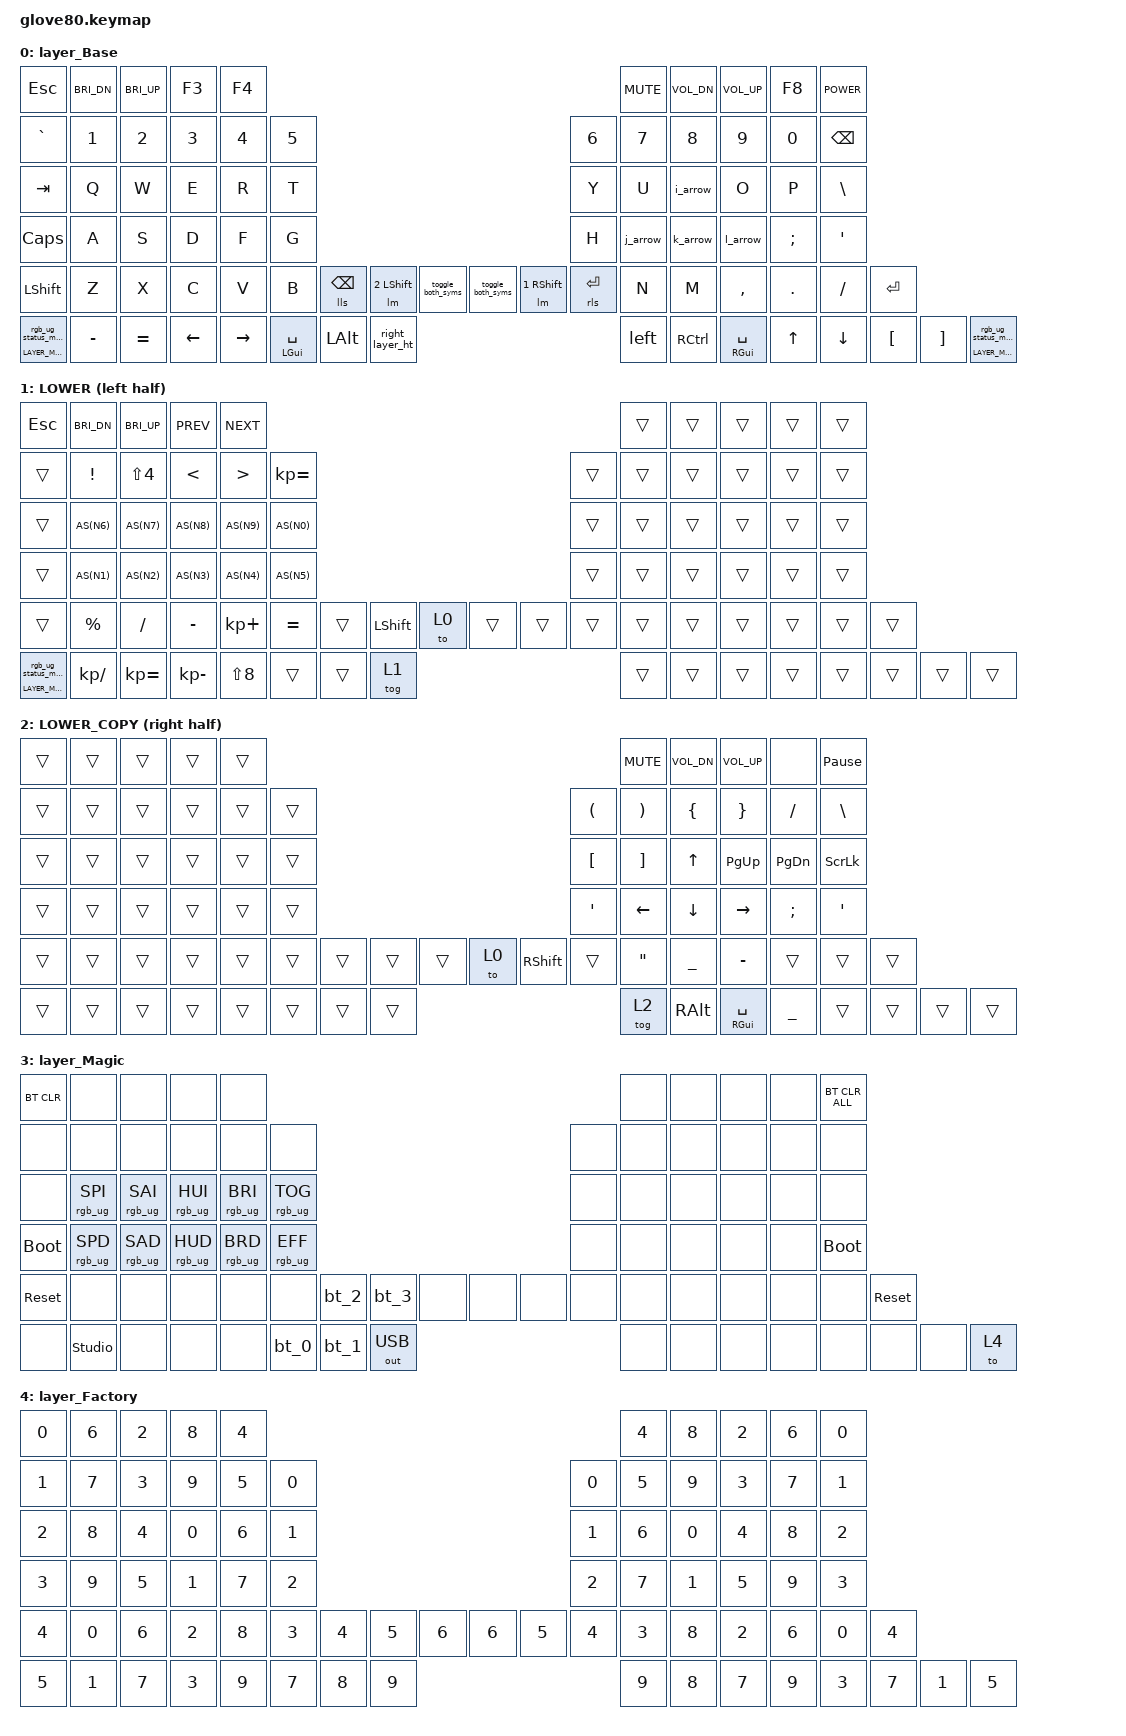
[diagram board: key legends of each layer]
/*
 * Copyright (c) 2020 The ZMK Contributors
 * Copyright (c) 2025 Innaworks Development Limited, trading as MoErgo
 *
 * SPDX-License-Identifier: MIT
 */
/* THIS FILE WAS GENERATED BY GLOVE80 LAYOUT EDITOR
 *
 * This file was generated automatically. You may or may not want to
 * edit it directly.
 */
/* Include all behavior includes needed */

#include <behaviors.dtsi>
#include <dt-bindings/zmk/bt.h>
#include <dt-bindings/zmk/keys.h>
#include <dt-bindings/zmk/outputs.h>
#include <dt-bindings/zmk/rgb.h>

/* On demand includes */
/* Automatically generated layer name #define */

#define LAYER_Base 0
#define LAYER_Left 1
#define LAYER_Right 2
#define LAYER_Magic 3
#define LAYER_Factory 4

/* To deal with the situation where there is no Lower layer, to keep &lower happy */
    /* Custom Device-tree */
#ifndef LAYER_Lower

#define LAYER_Lower 0

#endif
#define AS(keycode) &as LS(keycode) keycode
/{

    /* Input Listeners */
    /* System behavior and Macros */



    behaviors {
        // For the "layer" key, it'd nice to be able to use it as either a shift or a toggle.
        // Configure it as a tap dance, so the first tap (or hold) is a &mo and the second tap is a &to


        toggle_both_syms: toggle_both_syms {
            compatible = "zmk,behavior-macro";
            #binding-cells = <0>;
            wait-ms = <0>;
            tap-ms = <0>;
            bindings =
                <&macro_press>,
                <&tog LAYER_Left &tog LAYER_Right>,
                <&macro_release>;
        };

        left: left {
            compatible = "zmk,behavior-tap-dance";
            #binding-cells = <0>;
            tapping-term-ms = <200>;
            bindings = <&mo LAYER_Left>, <&to LAYER_Left>;
        };


        right_layer_ht: right_layer_ht {
            compatible = "zmk,behavior-tap-dance";           
            #binding-cells = <0>;
            tapping-term-ms = <200>;
            bindings = <&mo 2>, <&to 2>;  
        };

        mt_space_gui: mt_space_gui {
            compatible = "zmk,behavior-hold-tap";
            #binding-cells = <2>;
            flavor = "tap-preferred";      /* quicker to recognise holds */
            tapping-term-ms = <150>;  
            bindings = <&kp  &kp>;
        };
    };
};

/ {
    macros {
        rgb_ug_status_macro: rgb_ug_status_macro {
            compatible = "zmk,behavior-macro";
            #binding-cells = <0>;
            bindings = <&rgb_ug RGB_STATUS>;
        };
        lm: lm {
            compatible = "zmk,behavior-macro-two-param";
            wait-ms = <0>;
            tap-ms = <0>;
            #binding-cells = <2>;
            bindings
                = <&macro_param_1to1>
                , <&macro_press &mo MACRO_PLACEHOLDER>
                , <&macro_param_2to1>
                , <&macro_press &kp MACRO_PLACEHOLDER>
                , <&macro_pause_for_release>
                , <&macro_param_2to1>
                , <&macro_release &kp MACRO_PLACEHOLDER>
                , <&macro_param_1to1>
                , <&macro_release &mo MACRO_PLACEHOLDER>
                ;
        };

        lls: lls {
            compatible = "zmk,behavior-macro";
            #binding-cells = <0>;
            bindings
                = <&macro_press &lm 2 LSHIFT>
                , <&macro_pause_for_release>
                , <&macro_release &lm 2 LSHIFT>
                 ;
        };

        rls: rls {
            compatible = "zmk,behavior-macro";
            #binding-cells = <0>;
            bindings
                = <&macro_press &lm 1 RSHIFT>
                , <&macro_pause_for_release>
                , <&macro_release &lm 1 RSHIFT>
                 ;
        };
        
        
        
    };
};

/ {
    #ifdef BT_DISC_CMD

    behaviors {
        bt_0: bt_0 {
            compatible = "zmk,behavior-tap-dance";
            #binding-cells = <0>;
            tapping-term-ms = <200>;
            bindings = <&bt_select_0>, <&bt BT_DISC 0>;
        };

        bt_1: bt_1 {
            compatible = "zmk,behavior-tap-dance";
            #binding-cells = <0>;
            tapping-term-ms = <200>;
            bindings = <&bt_select_1>, <&bt BT_DISC 1>;
        };

        bt_2: bt_2 {
            compatible = "zmk,behavior-tap-dance";
            #binding-cells = <0>;
            tapping-term-ms = <200>;
            bindings = <&bt_select_2>, <&bt BT_DISC 2>;
        };

        bt_3: bt_3 {
            compatible = "zmk,behavior-tap-dance";
            #binding-cells = <0>;
            tapping-term-ms = <200>;
            bindings = <&bt_select_3>, <&bt BT_DISC 3>;
        };
    };

    macros {
        bt_select_0: bt_select_0 {
            compatible = "zmk,behavior-macro";
            #binding-cells = <0>;
            bindings = <&out OUT_BLE &bt BT_SEL 0>;
        };

        bt_select_1: bt_select_1 {
            compatible = "zmk,behavior-macro";
            #binding-cells = <0>;
            bindings = <&out OUT_BLE &bt BT_SEL 1>;
        };

        bt_select_2: bt_select_2 {
            compatible = "zmk,behavior-macro";
            #binding-cells = <0>;
            bindings = <&out OUT_BLE &bt BT_SEL 2>;
        };

        bt_select_3: bt_select_3 {
            compatible = "zmk,behavior-macro";
            #binding-cells = <0>;
            bindings = <&out OUT_BLE &bt BT_SEL 3>;
        };
    };

    #else

    macros {
        bt_0: bt_0 {
            compatible = "zmk,behavior-macro";
            #binding-cells = <0>;
            bindings = <&out OUT_BLE &bt BT_SEL 0>;
        };

        bt_1: bt_1 {
            compatible = "zmk,behavior-macro";
            #binding-cells = <0>;
            bindings = <&out OUT_BLE &bt BT_SEL 1>;
        };

        bt_2: bt_2 {
            compatible = "zmk,behavior-macro";
            #binding-cells = <0>;
            bindings = <&out OUT_BLE &bt BT_SEL 2>;
        };

        bt_3: bt_3 {
            compatible = "zmk,behavior-macro";
            #binding-cells = <0>;
            bindings = <&out OUT_BLE &bt BT_SEL 3>;
        };
    };

    #endif
};

/ {
    behaviors {
        magic: magic {
            compatible = "zmk,behavior-hold-tap";
            #binding-cells = <2>;
            flavor = "tap-preferred";
            tapping-term-ms = <200>;
            bindings = <&mo>, <&rgb_ug_status_macro>;
        };
        lmht: lmht {
            compatible = "zmk,behavior-hold-tap";
            flavor = "tap-preferred";
            tapping-term-ms = <300>;
            #binding-cells = <2>;
            bindings = <&lls>, <&kp >;
        };
        rmht: rmht {
            compatible = "zmk,behavior-hold-tap";
            flavor = "tap-preferred";
            tapping-term-ms = <300>;
            #binding-cells = <2>;
            bindings = <&rls>, <&kp>;
        }; 
    };
};

/* #define for key positions */

#define POS_LH_T1 52
#define POS_LH_T2 53
#define POS_LH_T3 54
#define POS_LH_T4 69
#define POS_LH_T5 70
#define POS_LH_T6 71
#define POS_LH_C1R2 15
#define POS_LH_C1R3 27
#define POS_LH_C1R4 39
#define POS_LH_C1R5 51
#define POS_LH_C2R1 4
#define POS_LH_C2R2 14
#define POS_LH_C2R3 26
#define POS_LH_C2R4 38
#define POS_LH_C2R5 50
#define POS_LH_C2R6 68
#define POS_LH_C3R1 3
#define POS_LH_C3R2 13
#define POS_LH_C3R3 25
#define POS_LH_C3R4 37
#define POS_LH_C3R5 49
#define POS_LH_C3R6 67
#define POS_LH_C4R1 2
#define POS_LH_C4R2 12
#define POS_LH_C4R3 24
#define POS_LH_C4R4 36
#define POS_LH_C4R5 48
#define POS_LH_C4R6 66
#define POS_LH_C5R1 1
#define POS_LH_C5R2 11
#define POS_LH_C5R3 23
#define POS_LH_C5R4 35
#define POS_LH_C5R5 47
#define POS_LH_C5R6 65
#define POS_LH_C6R1 0
#define POS_LH_C6R2 10
#define POS_LH_C6R3 22
#define POS_LH_C6R4 34
#define POS_LH_C6R5 46
#define POS_LH_C6R6 64
#define POS_RH_T1 57
#define POS_RH_T2 56
#define POS_RH_T3 55
#define POS_RH_T4 74
#define POS_RH_T5 73
#define POS_RH_T6 72
#define POS_RH_C1R2 16
#define POS_RH_C1R3 28
#define POS_RH_C1R4 40
#define POS_RH_C1R5 58
#define POS_RH_C2R1 5
#define POS_RH_C2R2 17
#define POS_RH_C2R3 29
#define POS_RH_C2R4 41
#define POS_RH_C2R5 59
#define POS_RH_C2R6 75
#define POS_RH_C3R1 6
#define POS_RH_C3R2 18
#define POS_RH_C3R3 30
#define POS_RH_C3R4 42
#define POS_RH_C3R5 60
#define POS_RH_C3R6 76
#define POS_RH_C4R1 7
#define POS_RH_C4R2 19
#define POS_RH_C4R3 31
#define POS_RH_C4R4 43
#define POS_RH_C4R5 61
#define POS_RH_C4R6 77
#define POS_RH_C5R1 8
#define POS_RH_C5R2 20
#define POS_RH_C5R3 32
#define POS_RH_C5R4 44
#define POS_RH_C5R5 62
#define POS_RH_C5R6 78
#define POS_RH_C6R1 9
#define POS_RH_C6R2 21
#define POS_RH_C6R3 33
#define POS_RH_C6R4 45
#define POS_RH_C6R5 63
#define POS_RH_C6R6 79

/* Custom Defined Behaviors */

/ {
    behaviors {
        /* Unique node-names instead of unit-addresses */

        j_arrow: behavior-mod-morph-j {
            compatible = "zmk,behavior-mod-morph";
            #binding-cells = <0>;
            mods       = <(MOD_LALT|MOD_LGUI)>;
            keep-mods  = <(MOD_LALT|MOD_LGUI)>;
            bindings   = <&kp J>, <&kp LEFT>;
        };
        k_arrow: behavior-mod-morph-k {
            compatible = "zmk,behavior-mod-morph";
            #binding-cells = <0>;
            mods       = <(MOD_LALT|MOD_LGUI)>;
            keep-mods  = <(MOD_LALT|MOD_LGUI)>;
            bindings   = <&kp K>, <&kp DOWN>;
        };
        l_arrow: behavior-mod-morph-l {
            compatible = "zmk,behavior-mod-morph";
            #binding-cells = <0>;
            mods       = <(MOD_LALT|MOD_LGUI)>;
            keep-mods  = <(MOD_LALT|MOD_LGUI)>;
            bindings   = <&kp L>, <&kp RIGHT>;
        };
        i_arrow: behavior-mod-morph-i {
            compatible = "zmk,behavior-mod-morph";
            #binding-cells = <0>;
            mods       = <(MOD_LALT|MOD_LGUI)>;
            keep-mods  = <(MOD_LALT|MOD_LGUI)>;
            bindings   = <&kp I>, <&kp UP>;
        };
        as: auto_shift {
            compatible = "zmk,behavior-hold-tap";
            #binding-cells = <2>;
            tapping_term_ms = <300>;
            quick_tap_ms = <0>;
            flavor = "tap-preferred";
            bindings = <&kp>, <&kp>;
        };
    };
};

/* Automatically generated macro definitions */

/ {
    macros {
    };
};

/* Automatically generated behavior definitions */

/ {
    behaviors {
    };
};

/* Automatically generated combos definitions */
/* Automatically generated keymap */

/ {
    keymap {
        compatible = "zmk,keymap";

        layer_Base {
            bindings = <
&kp ESC               &kp C_BRI_DN  &kp C_BRI_UP  &kp F3    &kp F4                                                                                                           &kp K_MUTE  &kp K_VOL_DN  &kp K_VOL_UP  &kp F8    &kp K_POWER
&kp GRAVE             &kp N1        &kp N2        &kp N3    &kp N4     &kp N5                                                                                        &kp N6  &kp N7      &kp N8        &kp N9        &kp N0    &kp BSPC
&kp TAB               &kp Q         &kp W         &kp E     &kp R      &kp T                                                                                         &kp Y   &kp U       &i_arrow      &kp O         &kp P     &kp BSLH
&kp CAPS              &kp A         &kp S         &kp D     &kp F      &kp G                                                                                         &kp H    &j_arrow    &k_arrow      &l_arrow      &kp SEMI  &kp SQT
&kp LSHFT             &kp Z         &kp X         &kp C     &kp V      &kp B   &lmht 0 BSPC  &lm 2 LSHFT  &toggle_both_syms    &toggle_both_syms  &lm 1 RSHFT  &rmht 0 RET     &kp N   &kp M       &kp COMMA     &kp DOT       &kp FSLH  &kp RET
&magic LAYER_Magic 0  &kp MINUS     &kp EQUAL     &kp LEFT  &kp RIGHT          &mt_space_gui  LGUI SPACE  &kp LALT  &right_layer_ht                      &left    &kp RCTRL   &mt_space_gui  RGUI SPACE         &kp UP      &kp DOWN      &kp LBKT      &kp RBKT  &magic LAYER_Magic 0
            >;
        };


        layer_Left {
            display-name = "LOWER (left half)";
            bindings = <
&kp ESC &kp C_BRI_DN          &kp C_BRI_UP  &kp C_PREV    &kp C_NEXT                                                                                 &trans  &trans  &trans  &trans  &trans
&trans                &kp EXCL      &kp LS(N4)    &kp LT        &kp GT       &kp KP_EQUAL                                                       &trans  &trans  &trans  &trans  &trans  &trans
&trans                AS(N6)    AS(N7)    AS(N8)    AS(N9)    AS(N0)                                                       &trans  &trans  &trans  &trans  &trans  &trans
&trans                AS(N1)    AS(N2)    AS(N3)    AS(N4)    AS(N5)                                                       &trans  &trans  &trans  &trans  &trans  &trans
&trans                &kp PRCNT     &kp FSLH      &kp MINUS     &kp KP_PLUS  &kp EQUAL     &trans  &kp LSHFT  &to 0     &trans  &trans  &trans  &trans  &trans  &trans  &trans  &trans  &trans
&magic LAYER_Magic 0  &kp KP_SLASH  &kp KP_EQUAL  &kp KP_MINUS  &kp LS(N8)                 &trans  &trans     &tog 1    &trans  &trans  &trans          &trans  &trans  &trans  &trans  &trans
            >;
        };

        layer_Right {
            display-name = "LOWER_COPY (right half)";
            bindings = <
&trans  &trans  &trans  &trans  &trans                                                                                       &kp C_MUTE      &kp C_VOL_DN  &kp C_VOL_UP  &none      &kp PAUSE_BREAK
&trans  &trans  &trans  &trans  &trans  &trans                                                         &kp LEFT_PARENTHESIS  &kp RPAR        &kp LBRC      &kp RBRC      &kp FSLH   &kp BSLH
&trans  &trans  &trans  &trans  &trans  &trans                                                         &kp LBKT              &kp RBKT        &kp UP        &kp PG_UP     &kp PG_DN  &kp SCROLLLOCK
&trans  &trans  &trans  &trans  &trans  &trans                                                         &kp SQT               &kp LEFT        &kp DOWN      &kp RIGHT     &kp SEMI   &kp SQT
&trans  &trans  &trans  &trans  &trans  &trans  &trans  &trans  &trans    &to 0   &kp RSHFT  &trans    &kp DOUBLE_QUOTES     &kp UNDERSCORE       &kp MINUS        &trans        &trans     &trans
&trans  &trans  &trans  &trans  &trans          &trans  &trans  &trans    &tog 2  &kp RALT   &mt_space_gui    RGUI  SPACE                  &kp UNDERSCORE  &trans        &trans        &trans     &trans
            >;
        };

        layer_Magic {
            bindings = <
&bt BT_CLR   &none            &none            &none            &none                                                                                       &none  &none  &none  &none  &bt BT_CLR_ALL
&none        &none            &none            &none            &none            &none                                                               &none  &none  &none  &none  &none  &none
&none        &rgb_ug RGB_SPI  &rgb_ug RGB_SAI  &rgb_ug RGB_HUI  &rgb_ug RGB_BRI  &rgb_ug RGB_TOG                                                     &none  &none  &none  &none  &none  &none
&bootloader  &rgb_ug RGB_SPD  &rgb_ug RGB_SAD  &rgb_ug RGB_HUD  &rgb_ug RGB_BRD  &rgb_ug RGB_EFF                                                     &none  &none  &none  &none  &none  &bootloader
&sys_reset   &none            &none            &none            &none            &none            &bt_2  &bt_3  &none           &none  &none  &none  &none  &none  &none  &none  &none  &sys_reset
&none        &studio_unlock            &none            &none            &none                             &bt_0  &bt_1  &out OUT_USB    &none  &none  &none         &none  &none  &none  &none  &to 4
            >;
        };

        layer_Factory {
            bindings = <
&kp NUMBER_0  &kp NUMBER_6  &kp NUMBER_2  &kp NUMBER_8  &kp NUMBER_4                                                                                                                    &kp NUMBER_4  &kp NUMBER_8  &kp NUMBER_2  &kp NUMBER_6  &kp NUMBER_0
&kp NUMBER_1  &kp NUMBER_7  &kp NUMBER_3  &kp NUMBER_9  &kp NUMBER_5  &kp NUMBER_0                                                                                        &kp NUMBER_0  &kp NUMBER_5  &kp NUMBER_9  &kp NUMBER_3  &kp NUMBER_7  &kp NUMBER_1
&kp NUMBER_2  &kp NUMBER_8  &kp NUMBER_4  &kp NUMBER_0  &kp NUMBER_6  &kp NUMBER_1                                                                                        &kp NUMBER_1  &kp NUMBER_6  &kp NUMBER_0  &kp NUMBER_4  &kp NUMBER_8  &kp NUMBER_2
&kp NUMBER_3  &kp NUMBER_9  &kp NUMBER_5  &kp NUMBER_1  &kp NUMBER_7  &kp NUMBER_2                                                                                        &kp NUMBER_2  &kp NUMBER_7  &kp NUMBER_1  &kp NUMBER_5  &kp NUMBER_9  &kp NUMBER_3
&kp NUMBER_4  &kp NUMBER_0  &kp NUMBER_6  &kp NUMBER_2  &kp NUMBER_8  &kp NUMBER_3  &kp NUMBER_4  &kp NUMBER_5  &kp NUMBER_6    &kp NUMBER_6  &kp NUMBER_5  &kp NUMBER_4  &kp NUMBER_3  &kp NUMBER_8  &kp NUMBER_2  &kp NUMBER_6  &kp NUMBER_0  &kp NUMBER_4
&kp NUMBER_5  &kp NUMBER_1  &kp NUMBER_7  &kp NUMBER_3  &kp NUMBER_9                &kp NUMBER_7  &kp NUMBER_8  &kp NUMBER_9    &kp NUMBER_9  &kp NUMBER_8  &kp NUMBER_7                &kp NUMBER_9  &kp NUMBER_3  &kp NUMBER_7  &kp NUMBER_1  &kp NUMBER_5
            >;
        };
    };
};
